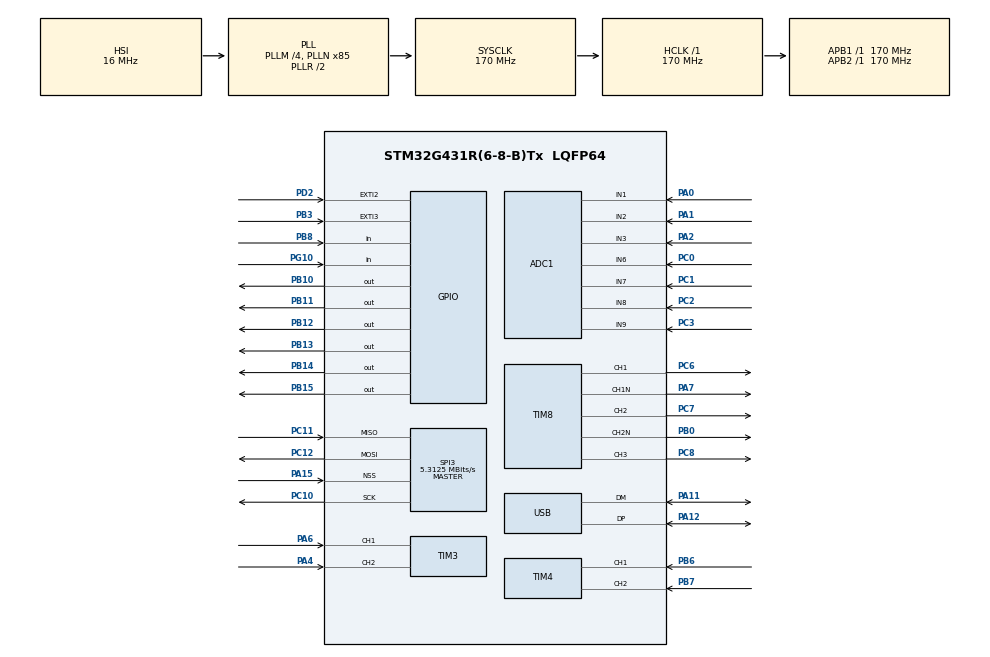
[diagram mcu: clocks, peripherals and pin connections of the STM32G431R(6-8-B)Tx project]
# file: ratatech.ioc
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ADC1.Channel-1\#ChannelRegularConversion=ADC_CHANNEL_1
ADC1.NbrOfConversionFlag=1
ADC1.OffsetNumber-1\#ChannelRegularConversion=ADC_OFFSET_NONE
ADC1.Rank-1\#ChannelRegularConversion=1
ADC1.SamplingTime-1\#ChannelRegularConversion=ADC_SAMPLETIME_2CYCLES_5
ADC1.master=1
Mcu.Family=STM32G4
Mcu.Name=STM32G431R(6-8-B)Tx
Mcu.Package=LQFP64
NVIC.PriorityGroup=NVIC_PRIORITYGROUP_4
PA0.Mode=IN1-Single-Ended
PA0.Signal=ADC1_IN1
PA1.Mode=IN2-Single-Ended
PA1.Signal=ADC1_IN2
PA11.Mode=Device
PA11.Signal=USB_DM
PA12.Mode=Device
PA12.Signal=USB_DP
PA13.Mode=Serial_Wire
PA13.Signal=SYS_JTMS-SWDIO
PA14.Mode=Serial_Wire
PA14.Signal=SYS_JTCK-SWCLK
PA15.Mode=NSS_Signal_Hard_Input
PA15.Signal=SPI3_NSS
PA2.Mode=IN3-Single-Ended
PA2.Signal=ADC1_IN3
PA4.Signal=S_TIM3_CH2
PA6.Signal=S_TIM3_CH1
PA7.Mode=PWM Generation1 CH1 CH1N
PA7.Signal=TIM8_CH1N
PB0.Mode=PWM Generation2 CH2 CH2N
PB0.Signal=TIM8_CH2N
PB10.Signal=GPIO_Output
PB11.Signal=GPIO_Output
PB12.Signal=GPIO_Output
PB13.Signal=GPIO_Output
PB14.Signal=GPIO_Output
PB15.Signal=GPIO_Output
PB3.Signal=GPXTI3
PB6.Signal=S_TIM4_CH1
PB7.Signal=S_TIM4_CH2
PB8-BOOT0.Signal=GPIO_Input
PC0.Mode=IN6-Single-Ended
PC0.Signal=ADC1_IN6
PC1.Mode=IN7-Single-Ended
PC1.Signal=ADC1_IN7
PC10.Mode=Full_Duplex_Master
PC10.Signal=SPI3_SCK
PC11.Mode=Full_Duplex_Master
PC11.Signal=SPI3_MISO
PC12.Mode=Full_Duplex_Master
PC12.Signal=SPI3_MOSI
PC2.Mode=IN8-Single-Ended
PC2.Signal=ADC1_IN8
PC3.Mode=IN9-Single-Ended
PC3.Signal=ADC1_IN9
PC6.Signal=S_TIM8_CH1
PC7.Signal=S_TIM8_CH2
PC8.Signal=S_TIM8_CH3
PD2.Signal=GPXTI2
PG10-NRST.Signal=GPIO_Input
ProjectManager.HeapSize=0x200
ProjectManager.StackSize=0x400
ProjectManager.TargetToolchain=CMake
RCC.ADC12Freq_Value=170000000
RCC.AHBFreq_Value=170000000
RCC.APB1Freq_Value=170000000
RCC.APB1TimFreq_Value=170000000
RCC.APB2Freq_Value=170000000
RCC.APB2TimFreq_Value=170000000
RCC.CK48CLockSelection=RCC_USBCLKSOURCE_HSI48
RCC.CortexFreq_Value=170000000
RCC.EXTERNAL_CLOCK_VALUE=12288000
RCC.HCLKFreq_Value=170000000
RCC.HSE_VALUE=8000000
RCC.HSI14CalibrationValue=16
RCC.HSI48_VALUE=48000000
RCC.HSI_VALUE=16000000
RCC.LSE_VALUE=32768
RCC.PLLM=RCC_PLLM_DIV4
RCC.PLLN=85
RCC.SYSCLKFreq_VALUE=170000000
RCC.SYSCLKSource=RCC_SYSCLKSOURCE_PLLCLK
RCC.USBFreq_Value=48000000
RCC.VCOOutputFreq_Value=340000000
SH.S_TIM3_CH1.0=TIM3_CH1,Encoder_Interface
SH.S_TIM3_CH2.0=TIM3_CH2,Encoder_Interface
SH.S_TIM4_CH1.0=TIM4_CH1,Encoder_Interface
SH.S_TIM4_CH2.0=TIM4_CH2,Encoder_Interface
SH.S_TIM8_CH1.0=TIM8_CH1,PWM Generation1 CH1 CH1N
SH.S_TIM8_CH2.0=TIM8_CH2,PWM Generation2 CH2 CH2N
SH.S_TIM8_CH3.0=TIM8_CH3,PWM Generation3 CH3
SPI3.BaudRatePrescaler=SPI_BAUDRATEPRESCALER_32
SPI3.CalculateBaudRate=5.3125 MBits/s
SPI3.Direction=SPI_DIRECTION_2LINES
SPI3.Mode=SPI_MODE_MASTER
SPI3.VirtualNSS=VM_NSSHARD
SPI3.VirtualType=VM_MASTER
TIM8.Channel-PWM\ Generation1\ CH1\ CH1N=TIM_CHANNEL_1
TIM8.Channel-PWM\ Generation2\ CH2\ CH2N=TIM_CHANNEL_2
TIM8.Channel-PWM\ Generation3\ CH3=TIM_CHANNEL_3
VP_CORDIC_VS_CORDIC.Mode=CORDIC_Activate
VP_FMAC_VS_FMAC.Mode=FMAC_Activate
VP_RCC_VS_USB.Mode=USB_FS
VP_SYS_VS_DBSignals.Mode=DisableDeadBatterySignals
VP_TIM8_VS_ClockSourceINT.Mode=Internal
board=custom

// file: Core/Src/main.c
/* USER CODE BEGIN Header */
/**
  ******************************************************************************
  * @file           : main.c
  * @brief          : Main program body
  ******************************************************************************
  * @attention
  *
  * Copyright (c) 2026 STMicroelectronics.
  * All rights reserved.
  *
  * This software is licensed under terms that can be found in the LICENSE file
  * in the root directory of this software component.
  * If no LICENSE file comes with this software, it is provided AS-IS.
  *
  ******************************************************************************
  */
/* USER CODE END Header */
#include "main.h"
#include "adc.h"
#include "cordic.h"
#include "fmac.h"
#include "spi.h"
#include "tim.h"
#include "usb.h"
#include "gpio.h"

/* USER CODE BEGIN Includes */

#include "ratatech/app_main.h"

/* USER CODE END Includes */

void SystemClock_Config(void);

int main(void)
{

  /* MCU Configuration--------------------------------------------------------*/

  /* Reset of all peripherals, Initializes the Flash interface and the Systick. */
  HAL_Init();

  /* Configure the system clock */
  SystemClock_Config();

  /* Initialize all configured peripherals */
  MX_GPIO_Init();
  MX_ADC1_Init();
  MX_CORDIC_Init();
  MX_FMAC_Init();
  MX_SPI3_Init();
  MX_TIM3_Init();
  MX_TIM4_Init();
  MX_TIM8_Init();
  MX_USB_PCD_Init();
  /* USER CODE BEGIN 2 */

  app_main();

  /* USER CODE END 2 */

  /* Infinite loop */
  while (1)
  {

  }
}

void SystemClock_Config(void)
{
  RCC_OscInitTypeDef RCC_OscInitStruct = {0};
  RCC_ClkInitTypeDef RCC_ClkInitStruct = {0};
  RCC_CRSInitTypeDef pInit = {0};

  /** Configure the main internal regulator output voltage
  */
  HAL_PWREx_ControlVoltageScaling(PWR_REGULATOR_VOLTAGE_SCALE1_BOOST);

  /** Initializes the RCC Oscillators according to the specified parameters
  * in the RCC_OscInitTypeDef structure.
  */
  RCC_OscInitStruct.OscillatorType = RCC_OSCILLATORTYPE_HSI|RCC_OSCILLATORTYPE_HSI48;
  RCC_OscInitStruct.HSIState = RCC_HSI_ON;
  RCC_OscInitStruct.HSICalibrationValue = RCC_HSICALIBRATION_DEFAULT;
  RCC_OscInitStruct.HSI48State = RCC_HSI48_ON;
  RCC_OscInitStruct.PLL.PLLState = RCC_PLL_ON;
  RCC_OscInitStruct.PLL.PLLSource = RCC_PLLSOURCE_HSI;
  RCC_OscInitStruct.PLL.PLLM = RCC_PLLM_DIV4;
  RCC_OscInitStruct.PLL.PLLN = 85;
  RCC_OscInitStruct.PLL.PLLP = RCC_PLLP_DIV2;
  RCC_OscInitStruct.PLL.PLLQ = RCC_PLLQ_DIV2;
  RCC_OscInitStruct.PLL.PLLR = RCC_PLLR_DIV2;
  if (HAL_RCC_OscConfig(&RCC_OscInitStruct) != HAL_OK)
  {
    Error_Handler();
  }

  /** Initializes the CPU, AHB and APB buses clocks
  */
  RCC_ClkInitStruct.ClockType = RCC_CLOCKTYPE_HCLK|RCC_CLOCKTYPE_SYSCLK
                              |RCC_CLOCKTYPE_PCLK1|RCC_CLOCKTYPE_PCLK2;
  RCC_ClkInitStruct.SYSCLKSource = RCC_SYSCLKSOURCE_PLLCLK;
  RCC_ClkInitStruct.AHBCLKDivider = RCC_SYSCLK_DIV1;
  RCC_ClkInitStruct.APB1CLKDivider = RCC_HCLK_DIV1;
  RCC_ClkInitStruct.APB2CLKDivider = RCC_HCLK_DIV1;

  if (HAL_RCC_ClockConfig(&RCC_ClkInitStruct, FLASH_LATENCY_4) != HAL_OK)
  {
    Error_Handler();
  }

  /** Enable the SYSCFG APB clock
  */
  __HAL_RCC_CRS_CLK_ENABLE();

  /** Configures CRS
  */
  pInit.Prescaler = RCC_CRS_SYNC_DIV1;
  pInit.Source = RCC_CRS_SYNC_SOURCE_USB;
  pInit.Polarity = RCC_CRS_SYNC_POLARITY_RISING;
  pInit.ReloadValue = __HAL_RCC_CRS_RELOADVALUE_CALCULATE(48000000,1000);
  pInit.ErrorLimitValue = 34;
  pInit.HSI48CalibrationValue = 32;

  HAL_RCCEx_CRSConfig(&pInit);
}

void Error_Handler(void)
{
  __disable_irq();
  while (1)
  {
  }
}
